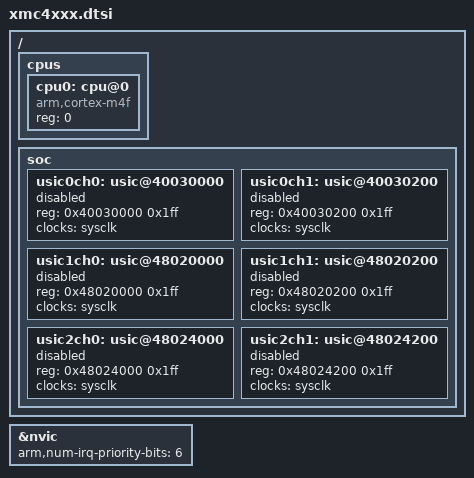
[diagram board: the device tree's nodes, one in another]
/*
 * Copyright (c) 2020 Linumiz
 * Author: Parthiban Nallathambi <parthiban@linumiz.com>
 *
 * SPDX-License-Identifier: Apache-2.0
 */

#include <arm/armv7-m.dtsi>

/ {
	cpus {
		#address-cells = <1>;
		#size-cells = <0>;

		cpu0: cpu@0 {
			compatible = "arm,cortex-m4f";
			reg = <0>;
		};
	};

	soc {
		usic0ch0: usic@40030000 {
			reg = <0x40030000 0x1ff>;
			clocks = <&sysclk>;
			status = "disabled";
		};

		usic0ch1: usic@40030200 {
			reg = <0x40030200 0x1ff>;
			clocks = <&sysclk>;
			status = "disabled";
		};

		usic1ch0: usic@48020000 {
			reg = <0x48020000 0x1ff>;
			clocks = <&sysclk>;
			status = "disabled";
		};

		usic1ch1: usic@48020200 {
			reg = <0x48020200 0x1ff>;
			clocks = <&sysclk>;
			status = "disabled";
		};

		usic2ch0: usic@48024000 {
			reg = <0x48024000 0x1ff>;
			clocks = <&sysclk>;
			status = "disabled";
		};

		usic2ch1: usic@48024200 {
			reg = <0x48024200 0x1ff>;
			clocks = <&sysclk>;
			status = "disabled";
		};
	};
};

&nvic {
	arm,num-irq-priority-bits = <6>;
};
